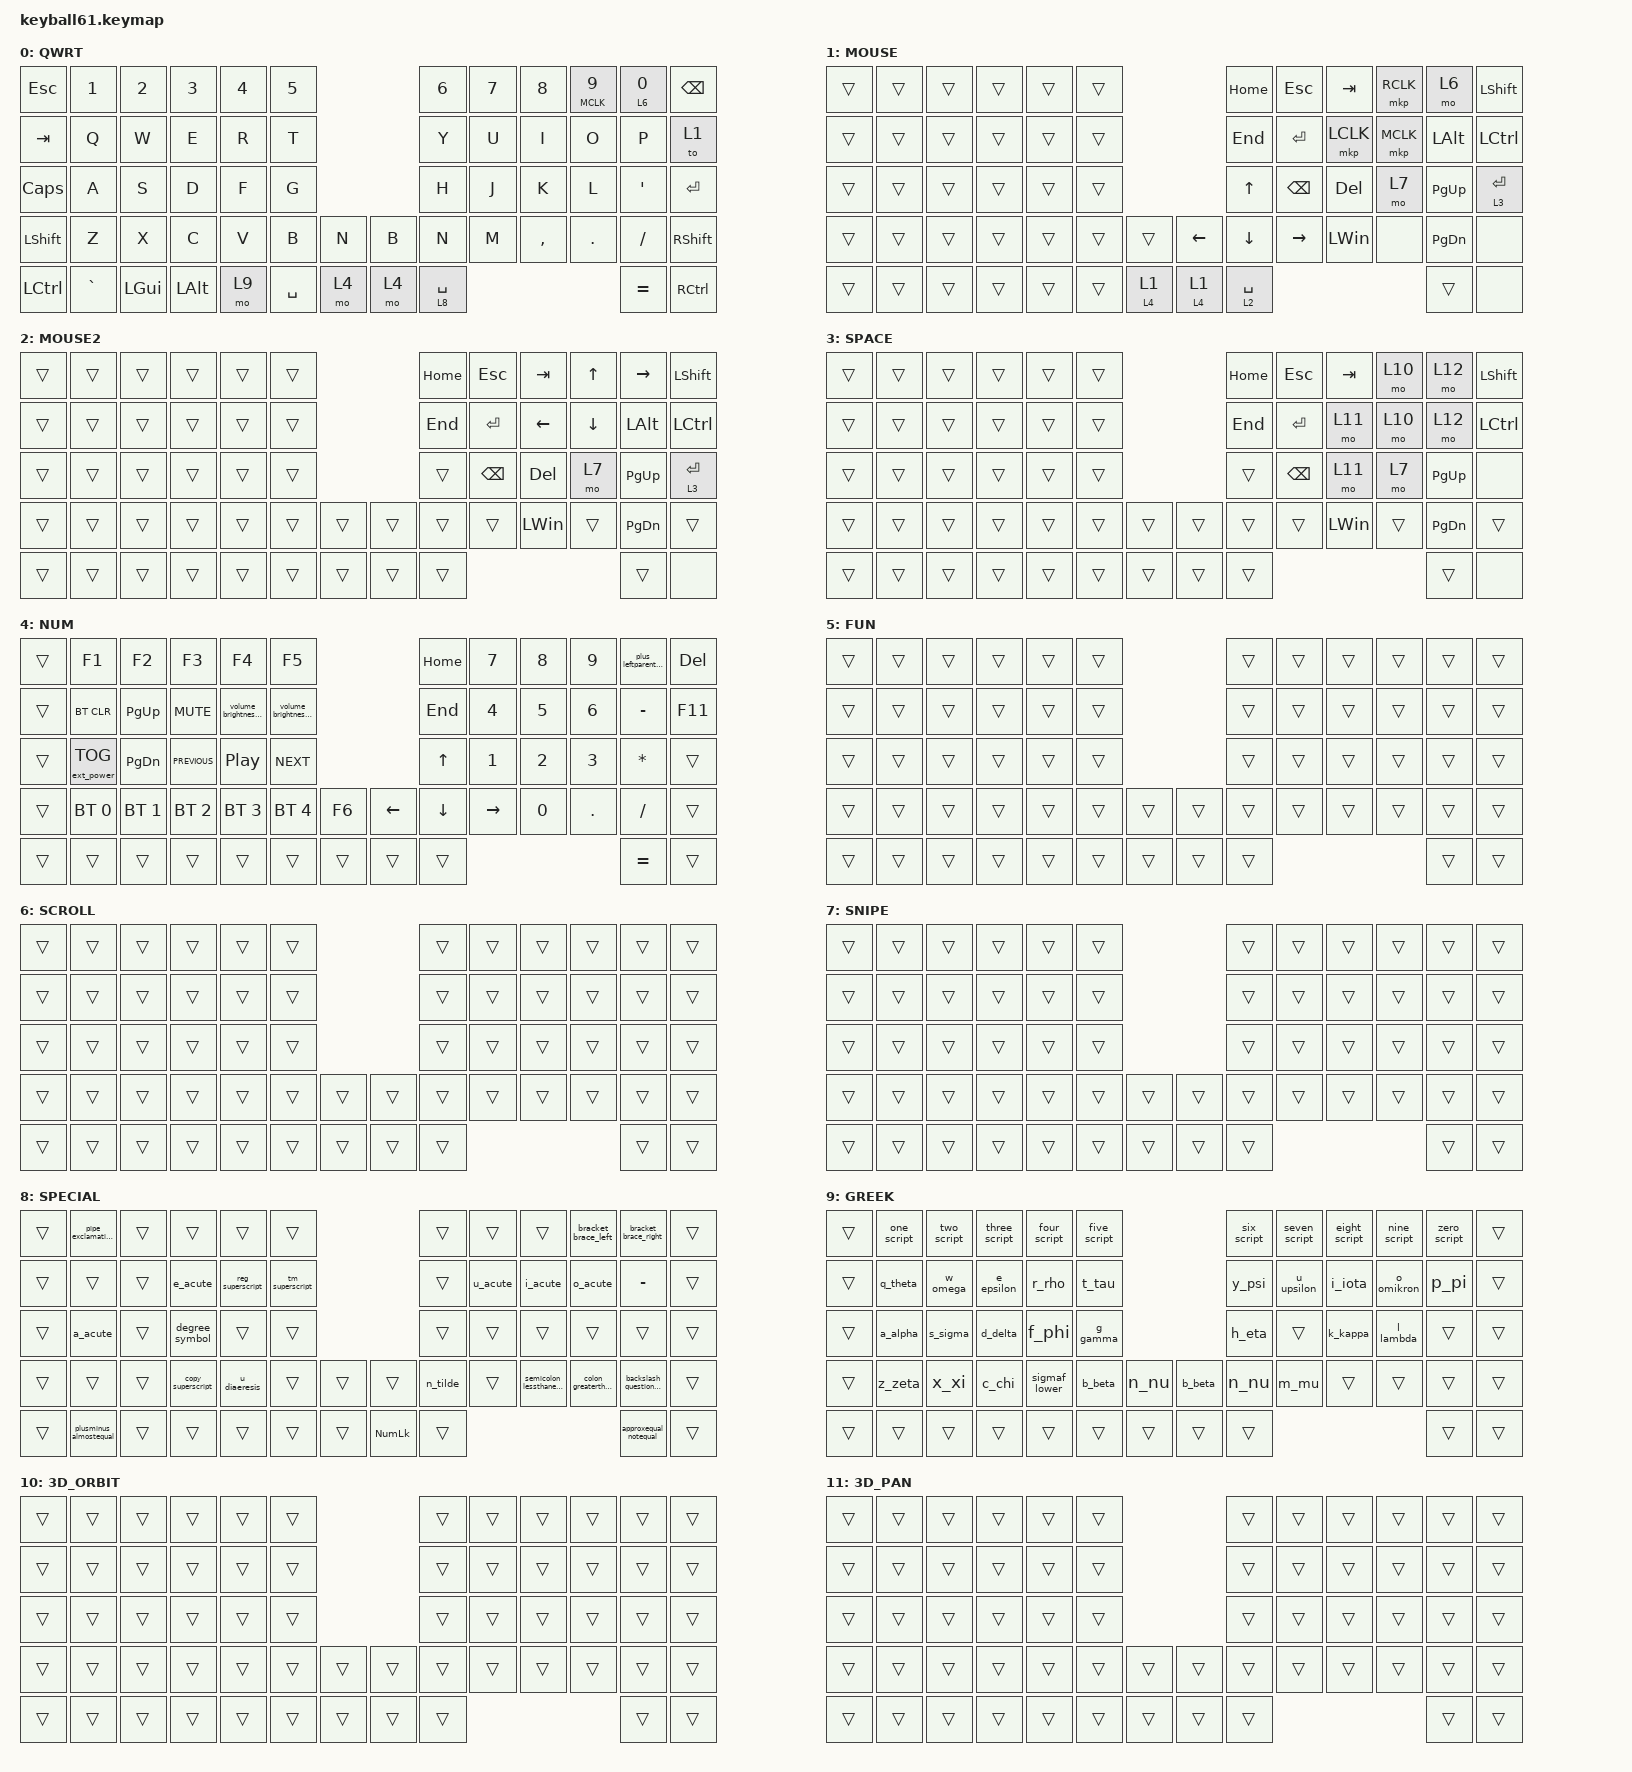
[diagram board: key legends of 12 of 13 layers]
#define DEFAULT 0
#define SYM     1
#define FUN     2
#define MOUSE   3
#define SCROLL  4
#define SNIPE   5

#include <dt-bindings/zmk/mouse.h>

//#include <dt-bindings/zmk/pointers.h>

#include <behaviors.dtsi>
#include <dt-bindings/zmk/bt.h>
#include <dt-bindings/zmk/ext_power.h>
#include <dt-bindings/zmk/keys.h>
#include <dt-bindings/zmk/pointing.h>

&lt {
    tapping-term-ms = <240>;
    flavor = "balanced";
    quick-tap-ms = <150>;
};

&mt {
    tapping-term-ms = <300>;
    flavor = "tap-preferred";
    quick-tap-ms = <150>;
};

/ {
    combos { compatible = "zmk,combos"; };

    behaviors {
        lmt0: lmt0 {
            compatible = "zmk,behavior-hold-tap";
            label = "Tap=&tog; Hold=&mo";
            bindings = <&mo>, <&tog>;

            #binding-cells = <2>;
            tapping-term-ms = <200>;
            flavor = "balanced";
        };

        lmt1: lmt1 {
            compatible = "zmk,behavior-hold-tap";
            label = "Tap=&tog; Hold=&kp";
            bindings = <&kp>, <&tog>;

            #binding-cells = <2>;
            tapping-term-ms = <250>;
            flavor = "balanced";
        };

        lmt2: lmt2 {
            compatible = "zmk,behavior-hold-tap";
            label = "Tap=&kp; Hold=&mkp";
            bindings = <&mkp>, <&kp>;

            #binding-cells = <2>;
            tapping-term-ms = <250>;
            flavor = "balanced";
        };

        td0: td0 {
            compatible = "zmk,behavior-tap-dance";
            label = "1tap=shift;2tap=&tog4";
            #binding-cells = <0>;
            bindings = <&kp LEFT_CONTROL>, <&tog 1>;
        };

        plus_leftparenthesis: plus_leftparenthesis {
            compatible = "zmk,behavior-mod-morph";
            label = "PLUS_LEFTPARENTHESIS";
            bindings = <&kp PLUS>, <&kp RIGHT_PARENTHESIS>;

            #binding-cells = <0>;
            mods = <(MOD_LSFT|MOD_RSFT)>;
        };

        volume_brightness_down: volume_brightness_down {
            compatible = "zmk,behavior-mod-morph";
            label = "VOLUME_BRIGHTNESS_DOWN";
            bindings = <&kp C_VOLUME_DOWN>, <&kp C_BRIGHTNESS_DEC>;

            #binding-cells = <0>;
            mods = <(MOD_LSFT|MOD_RSFT)>;
        };

        volume_brightness_up: volume_brightness_up {
            compatible = "zmk,behavior-mod-morph";
            label = "VOLUME_BRIGHTNESS_UP";
            bindings = <&kp C_VOLUME_UP>, <&kp C_BRIGHTNESS_INC>;

            #binding-cells = <0>;
            mods = <(MOD_LSFT|MOD_RSFT)>;
        };

        n_tilde: n_tilde {
            compatible = "zmk,behavior-mod-morph";
            label = "N_TILDE";
            bindings = <&n_tilde_lower>, <&n_tilde_upper>;

            #binding-cells = <0>;
            mods = <(MOD_LSFT|MOD_RSFT)>;
        };

        a_acute: a_acute {
            compatible = "zmk,behavior-mod-morph";
            label = "A_ACUTE";
            bindings = <&a_acute_lower>, <&a_acute_upper>;

            #binding-cells = <0>;
            mods = <(MOD_LSFT|MOD_RCTL)>;
        };

        e_acute: e_acute {
            compatible = "zmk,behavior-mod-morph";
            label = "E_ACUTE";
            bindings = <&e_acute_lower>, <&e_acute_upper>;

            #binding-cells = <0>;
            mods = <(MOD_LSFT|MOD_RCTL)>;
        };

        i_acute: i_acute {
            compatible = "zmk,behavior-mod-morph";
            label = "I_ACUTE";
            bindings = <&i_acute_lower>, <&i_acute_upper>;

            #binding-cells = <0>;
            mods = <(MOD_LSFT|MOD_RCTL)>;
        };

        o_acute: o_acute {
            compatible = "zmk,behavior-mod-morph";
            label = "O_ACUTE";
            bindings = <&o_acute_lower>, <&o_acute_upper>;

            #binding-cells = <0>;
            mods = <(MOD_LSFT|MOD_RCTL)>;
        };

        u_acute: u_acute {
            compatible = "zmk,behavior-mod-morph";
            label = "U_ACUTE";
            bindings = <&u_acute_lower>, <&u_acute_upper>;

            #binding-cells = <0>;
            mods = <(MOD_LSFT|MOD_RCTL)>;
        };

        u_diaeresis: u_diaeresis {
            compatible = "zmk,behavior-mod-morph";
            label = "U_DIAERESIS";
            bindings = <&u_diaeresis_lower>, <&u_diaeresis_upper>;

            #binding-cells = <0>;
            mods = <(MOD_LSFT|MOD_RCTL)>;
        };

        backslash_questionmarkreverse: backslash_questionmarkreverse {
            compatible = "zmk,behavior-mod-morph";
            label = "BACKSLASH_QUESTIONMARKREVERSE";
            bindings = <&kp BACKSLASH>, <&question_mark_reverse>;

            #binding-cells = <0>;
            mods = <(MOD_LSFT|MOD_RSFT)>;
        };

        semicolon_lessthanequal: semicolon_lessthanequal {
            compatible = "zmk,behavior-mod-morph";
            label = "SEMICOLON_LESSTHANEQUAL";
            bindings = <&kp SEMICOLON>, <&less_than_equal>;

            #binding-cells = <0>;
            mods = <(MOD_LSFT|MOD_RSFT)>;
        };

        colon_greaterthanequal: colon_greaterthanequal {
            compatible = "zmk,behavior-mod-morph";
            label = "COLON_GREATERTHANEQUAL";
            bindings = <&kp COLON>, <&greater_than_equal>;

            #binding-cells = <0>;
            mods = <(MOD_LSFT|MOD_RSFT)>;
        };

        approxequal_notequal: approxequal_notequal {
            compatible = "zmk,behavior-mod-morph";
            label = "APPROXEQUAL_NOTEQUAL";
            bindings = <&approx_equal>, <&not_equal>;

            #binding-cells = <0>;
            mods = <(MOD_LSFT|MOD_RSFT)>;
        };

        plusminus_almostequal: plusminus_almostequal {
            compatible = "zmk,behavior-mod-morph";
            label = "PLUSMINUS_ALMOSTEQUAL";
            bindings = <&plus_minus>, <&almost_equal>;

            #binding-cells = <0>;
            mods = <(MOD_LSFT|MOD_RSFT)>;
        };

        pipe_exclamationmarkreverse: pipe_exclamationmarkreverse {
            compatible = "zmk,behavior-mod-morph";
            label = "PIPE_EXCLAMATIONMARKREVERSE";
            bindings = <&kp PIPE>, <&exclamation_mark_reverse>;

            #binding-cells = <0>;
            mods = <(MOD_LSFT|MOD_RSFT)>;
        };

        bracket_brace_left: bracket_brace_left {
            compatible = "zmk,behavior-mod-morph";
            label = "BRACKET_BRACE_LEFT";
            bindings = <&kp LEFT_BRACKET>, <&kp LEFT_BRACE>;

            #binding-cells = <0>;
            mods = <(MOD_LSFT|MOD_RSFT)>;
        };

        bracket_brace_right: bracket_brace_right {
            compatible = "zmk,behavior-mod-morph";
            label = "BRACKET_BRACE_RIGHT";
            bindings = <&kp RIGHT_BRACKET>, <&kp RIGHT_BRACE>;

            #binding-cells = <0>;
            mods = <(MOD_LSFT|MOD_RSFT)>;
        };

        one_script: one_script {
            compatible = "zmk,behavior-mod-morph";
            label = "ONE_SCRIPT";
            bindings = <&one_subscript>, <&one_superscript>;

            #binding-cells = <0>;
            mods = <(MOD_LSFT|MOD_RSFT)>;
        };

        two_script: two_script {
            compatible = "zmk,behavior-mod-morph";
            label = "TWO_SCRIPT";
            bindings = <&two_subscript>, <&two_superscript>;

            #binding-cells = <0>;
            mods = <(MOD_LSFT|MOD_RSFT)>;
        };

        three_script: three_script {
            compatible = "zmk,behavior-mod-morph";
            label = "THREE_SCRIPT";
            bindings = <&three_subscript>, <&three_superscript>;

            #binding-cells = <0>;
            mods = <(MOD_LSFT|MOD_RSFT)>;
        };

        four_script: four_script {
            compatible = "zmk,behavior-mod-morph";
            label = "FOUR_SCRIPT";
            bindings = <&four_subscript>, <&four_superscript>;

            #binding-cells = <0>;
            mods = <(MOD_LSFT|MOD_RSFT)>;
        };

        five_script: five_script {
            compatible = "zmk,behavior-mod-morph";
            label = "FIVE_SCRIPT";
            bindings = <&five_subscript>, <&five_superscript>;

            #binding-cells = <0>;
            mods = <(MOD_LSFT|MOD_RSFT)>;
        };

        six_script: six_script {
            compatible = "zmk,behavior-mod-morph";
            label = "SIX_SCRIPT";
            bindings = <&six_subscript>, <&six_superscript>;

            #binding-cells = <0>;
            mods = <(MOD_LSFT|MOD_RSFT)>;
        };

        seven_script: seven_script {
            compatible = "zmk,behavior-mod-morph";
            label = "SEVEN_SCRIPT";
            bindings = <&seven_subscript>, <&seven_superscript>;

            #binding-cells = <0>;
            mods = <(MOD_LSFT|MOD_RSFT)>;
        };

        eight_script: eight_script {
            compatible = "zmk,behavior-mod-morph";
            label = "EIGHT_SCRIPT";
            bindings = <&eight_subscript>, <&eight_superscript>;

            #binding-cells = <0>;
            mods = <(MOD_LSFT|MOD_RSFT)>;
        };

        nine_script: nine_script {
            compatible = "zmk,behavior-mod-morph";
            label = "NINE_SCRIPT";
            bindings = <&nine_subscript>, <&nine_superscript>;

            #binding-cells = <0>;
            mods = <(MOD_LSFT|MOD_RSFT)>;
        };

        zero_script: zero_script {
            compatible = "zmk,behavior-mod-morph";
            label = "ZERO_SCRIPT";
            bindings = <&zero_subscript>, <&zero_superscript>;

            #binding-cells = <0>;
            mods = <(MOD_LSFT|MOD_RSFT)>;
        };

        a_alpha: a_alpha {
            compatible = "zmk,behavior-mod-morph";
            label = "A_ALPHA";
            bindings = <&alpha_lower>, <&alpha_upper>;

            #binding-cells = <0>;
            mods = <(MOD_LSFT|MOD_RSFT)>;
        };

        b_beta: b_beta {
            compatible = "zmk,behavior-mod-morph";
            label = "B_BETA";
            bindings = <&beta_lower>, <&beta_upper>;

            #binding-cells = <0>;
            mods = <(MOD_LSFT|MOD_RSFT)>;
        };

        g_gamma: g_gamma {
            compatible = "zmk,behavior-mod-morph";
            label = "G_GAMMA";
            bindings = <&gamma_lower>, <&gamma_upper>;

            #binding-cells = <0>;
            mods = <(MOD_LSFT|MOD_RSFT)>;
        };

        d_delta: d_delta {
            compatible = "zmk,behavior-mod-morph";
            label = "D_DELTA";
            bindings = <&delta_lower>, <&delta_upper>;

            #binding-cells = <0>;
            mods = <(MOD_LSFT|MOD_RSFT)>;
        };

        e_epsilon: e_epsilon {
            compatible = "zmk,behavior-mod-morph";
            label = "E_EPSILON";
            bindings = <&epsilon_lower>, <&epsilon_upper>;

            #binding-cells = <0>;
            mods = <(MOD_LSFT|MOD_RSFT)>;
        };

        z_zeta: z_zeta {
            compatible = "zmk,behavior-mod-morph";
            label = "Z_ZETA";
            bindings = <&zeta_lower>, <&zeta_upper>;

            #binding-cells = <0>;
            mods = <(MOD_LSFT|MOD_RSFT)>;
        };

        h_eta: h_eta {
            compatible = "zmk,behavior-mod-morph";
            label = "H_ETA";
            bindings = <&eta_lower>, <&eta_upper>;

            #binding-cells = <0>;
            mods = <(MOD_LSFT|MOD_RSFT)>;
        };

        q_theta: q_theta {
            compatible = "zmk,behavior-mod-morph";
            label = "Q_THETA";
            bindings = <&theta_lower>, <&theta_upper>;

            #binding-cells = <0>;
            mods = <(MOD_LSFT|MOD_RSFT)>;
        };

        i_iota: i_iota {
            compatible = "zmk,behavior-mod-morph";
            label = "I_IOTA";
            bindings = <&iota_lower>, <&iota_upper>;

            #binding-cells = <0>;
            mods = <(MOD_LSFT|MOD_RSFT)>;
        };

        k_kappa: k_kappa {
            compatible = "zmk,behavior-mod-morph";
            label = "K_KAPPA";
            bindings = <&kappa_lower>, <&kappa_upper>;

            #binding-cells = <0>;
            mods = <(MOD_LSFT|MOD_RSFT)>;
        };

        l_lambda: l_lambda {
            compatible = "zmk,behavior-mod-morph";
            label = "L_LAMBDA";
            bindings = <&lambda_lower>, <&lambda_upper>;

            #binding-cells = <0>;
            mods = <(MOD_LSFT|MOD_RSFT)>;
        };

        m_mu: m_mu {
            compatible = "zmk,behavior-mod-morph";
            label = "M_MU";
            bindings = <&mu_lower>, <&mu_upper>;

            #binding-cells = <0>;
            mods = <(MOD_LSFT|MOD_RSFT)>;
        };

        n_nu: n_nu {
            compatible = "zmk,behavior-mod-morph";
            label = "N_NU";
            bindings = <&nu_lower>, <&nu_upper>;

            #binding-cells = <0>;
            mods = <(MOD_LSFT|MOD_RSFT)>;
        };

        x_xi: x_xi {
            compatible = "zmk,behavior-mod-morph";
            label = "X_XI";
            bindings = <&xi_lower>, <&xi_upper>;

            #binding-cells = <0>;
            mods = <(MOD_LSFT|MOD_RSFT)>;
        };

        o_omikron: o_omikron {
            compatible = "zmk,behavior-mod-morph";
            label = "O_OMIKRON";
            bindings = <&omicron_lower>, <&omicron_upper>;

            #binding-cells = <0>;
            mods = <(MOD_LSFT|MOD_RSFT)>;
        };

        p_pi: p_pi {
            compatible = "zmk,behavior-mod-morph";
            label = "P_PI";
            bindings = <&pi_lower>, <&pi_upper>;

            #binding-cells = <0>;
            mods = <(MOD_LSFT|MOD_RSFT)>;
        };

        r_rho: r_rho {
            compatible = "zmk,behavior-mod-morph";
            label = "R_RHO";
            bindings = <&rho_lower>, <&rho_upper>;

            #binding-cells = <0>;
            mods = <(MOD_LSFT|MOD_RSFT)>;
        };

        s_sigma: s_sigma {
            compatible = "zmk,behavior-mod-morph";
            label = "S_SIGMA";
            bindings = <&sigma_lower>, <&sigma_upper>;

            #binding-cells = <0>;
            mods = <(MOD_LSFT|MOD_RSFT)>;
        };

        t_tau: t_tau {
            compatible = "zmk,behavior-mod-morph";
            label = "T_TAU";
            bindings = <&tau_lower>, <&tau_upper>;

            #binding-cells = <0>;
            mods = <(MOD_LSFT|MOD_RSFT)>;
        };

        u_upsilon: u_upsilon {
            compatible = "zmk,behavior-mod-morph";
            label = "U_UPSILON";
            bindings = <&upsilon_lower>, <&upsilon_upper>;

            #binding-cells = <0>;
            mods = <(MOD_LSFT|MOD_RSFT)>;
        };

        f_phi: f_phi {
            compatible = "zmk,behavior-mod-morph";
            label = "F_PHI";
            bindings = <&phi_lower>, <&phi_upper>;

            #binding-cells = <0>;
            mods = <(MOD_LSFT|MOD_RSFT)>;
        };

        c_chi: c_chi {
            compatible = "zmk,behavior-mod-morph";
            label = "C_CHI";
            bindings = <&chi_lower>, <&chi_upper>;

            #binding-cells = <0>;
            mods = <(MOD_LSFT|MOD_RSFT)>;
        };

        y_psi: y_psi {
            compatible = "zmk,behavior-mod-morph";
            label = "Y_PSI";
            bindings = <&psi_lower>, <&psi_upper>;

            #binding-cells = <0>;
            mods = <(MOD_LSFT|MOD_RSFT)>;
        };

        w_omega: w_omega {
            compatible = "zmk,behavior-mod-morph";
            label = "W_OMEGA";
            bindings = <&omega_lower>, <&omega_upper>;

            #binding-cells = <0>;
            mods = <(MOD_LSFT|MOD_RSFT)>;
        };
    };

    macros {
        n_tilde_lower: n_tilde_lower {
            compatible = "zmk,behavior-macro";
            #binding-cells = <0>;
            bindings =
                <&macro_press>,
                <&kp LEFT_ALT>,
                <&macro_tap>,
                <&kp KP_NUMBER_1 &kp KP_NUMBER_6 &kp KP_NUMBER_4>,
                <&macro_release>,
                <&kp LALT>;

            label = "N_TILDE_LOWER";
            wait-ms = <1>;
            tap-ms = <1>;
        };

        n_tilde_upper: n_tilde_upper {
            compatible = "zmk,behavior-macro";
            #binding-cells = <0>;
            bindings =
                <&macro_press>,
                <&kp LEFT_ALT>,
                <&macro_tap>,
                <&kp KP_NUMBER_1 &kp KP_NUMBER_6 &kp KP_NUMBER_5>,
                <&macro_release>,
                <&kp LALT>;

            label = "N_TILDE_UPPER";
            wait-ms = <1>;
            tap-ms = <1>;
        };

        a_acute_lower: a_acute_lower {
            compatible = "zmk,behavior-macro";
            #binding-cells = <0>;
            bindings =
                <&macro_press>,
                <&kp LEFT_ALT>,
                <&macro_tap>,
                <&kp KP_NUMBER_1 &kp KP_NUMBER_6 &kp KP_NUMBER_0>,
                <&macro_release>,
                <&kp LEFT_ALT>;

            label = "A_ACUTE_LOWER";
            wait-ms = <1>;
            tap-ms = <1>;
        };

        a_acute_upper: a_acute_upper {
            compatible = "zmk,behavior-macro";
            #binding-cells = <0>;
            bindings =
                <&macro_press>,
                <&kp LEFT_ALT>,
                <&macro_tap>,
                <&kp KP_NUMBER_0 &kp KP_NUMBER_1 &kp KP_NUMBER_9 &kp KP_NUMBER_3>,
                <&macro_release>,
                <&kp LEFT_ALT>;

            label = "A_ACUTE_UPPER";
            wait-ms = <1>;
            tap-ms = <1>;
        };

        e_acute_lower: e_acute_lower {
            compatible = "zmk,behavior-macro";
            #binding-cells = <0>;
            bindings =
                <&macro_press>,
                <&kp LEFT_ALT>,
                <&macro_tap>,
                <&kp KP_NUMBER_1 &kp KP_NUMBER_3 &kp KP_NUMBER_0>,
                <&macro_release>,
                <&kp LEFT_ALT>;

            label = "E_ACUTE_LOWER";
            wait-ms = <1>;
            tap-ms = <1>;
        };

        e_acute_upper: e_acute_upper {
            compatible = "zmk,behavior-macro";
            #binding-cells = <0>;
            bindings =
                <&macro_press>,
                <&kp LEFT_ALT>,
                <&macro_tap>,
                <&kp KP_NUMBER_1 &kp KP_NUMBER_4 &kp KP_NUMBER_4>,
                <&macro_release>,
                <&kp LEFT_ALT>;

            label = "E_ACUTE_UPPER";
            wait-ms = <1>;
            tap-ms = <1>;
        };

        i_acute_lower: i_acute_lower {
            compatible = "zmk,behavior-macro";
            #binding-cells = <0>;
            bindings =
                <&macro_press>,
                <&kp LEFT_ALT>,
                <&macro_tap>,
                <&kp KP_NUMBER_1 &kp KP_NUMBER_6 &kp KP_NUMBER_1>,
                <&macro_release>,
                <&kp LEFT_ALT>;

            label = "I_ACUTE_LOWER";
            wait-ms = <1>;
            tap-ms = <1>;
        };

        i_acute_upper: i_acute_upper {
            compatible = "zmk,behavior-macro";
            #binding-cells = <0>;
            bindings =
                <&macro_press>,
                <&kp LEFT_ALT>,
                <&macro_tap>,
                <&kp KP_NUMBER_0 &kp KP_NUMBER_2 &kp KP_NUMBER_0 &kp KP_NUMBER_5>,
                <&macro_release>,
                <&kp LEFT_ALT>;

            label = "I_ACUTE_UPPER";
            wait-ms = <1>;
            tap-ms = <1>;
        };

        o_acute_lower: o_acute_lower {
            compatible = "zmk,behavior-macro";
            #binding-cells = <0>;
            bindings =
                <&macro_press>,
                <&kp LEFT_ALT>,
                <&macro_tap>,
                <&kp KP_NUMBER_1 &kp KP_NUMBER_6 &kp KP_NUMBER_2>,
                <&macro_release>,
                <&kp LEFT_ALT>;

            label = "O_ACUTE_LOWER";
            wait-ms = <1>;
            tap-ms = <1>;
        };

        o_acute_upper: o_acute_upper {
            compatible = "zmk,behavior-macro";
            #binding-cells = <0>;
            bindings =
                <&macro_press>,
                <&kp LEFT_ALT>,
                <&macro_tap>,
                <&kp KP_NUMBER_0 &kp KP_NUMBER_2 &kp KP_NUMBER_1 &kp KP_NUMBER_1>,
                <&macro_release>,
                <&kp LEFT_ALT>;

            label = "O_ACUTE_UPPER";
            wait-ms = <1>;
            tap-ms = <1>;
        };

        u_acute_lower: u_acute_lower {
            compatible = "zmk,behavior-macro";
            #binding-cells = <0>;
            bindings =
                <&macro_press>,
                <&kp LEFT_ALT>,
                <&macro_tap>,
                <&kp KP_NUMBER_1 &kp KP_NUMBER_6 &kp KP_NUMBER_3>,
                <&macro_release>,
                <&kp LEFT_ALT>;

            label = "U_ACUTE_LOWER";
            wait-ms = <1>;
            tap-ms = <1>;
        };

        u_acute_upper: u_acute_upper {
            compatible = "zmk,behavior-macro";
            #binding-cells = <0>;
            bindings =
                <&macro_press>,
                <&kp LEFT_ALT>,
                <&macro_tap>,
                <&kp KP_NUMBER_0 &kp KP_NUMBER_2 &kp KP_NUMBER_1 &kp KP_NUMBER_8>,
                <&macro_release>,
                <&kp LEFT_ALT>;

            label = "U_ACUTE_UPPER";
            wait-ms = <1>;
            tap-ms = <1>;
        };

        u_diaeresis_lower: u_diaeresis_lower {
            compatible = "zmk,behavior-macro";
            #binding-cells = <0>;
            bindings =
                <&macro_press>,
                <&kp LEFT_ALT>,
                <&macro_tap>,
                <&kp KP_NUMBER_1 &kp KP_NUMBER_2 &kp KP_NUMBER_9>,
                <&macro_release>,
                <&kp LEFT_ALT>;

            label = "U_DIAERESIS_LOWER";
            wait-ms = <1>;
            tap-ms = <1>;
        };

        u_diaeresis_upper: u_diaeresis_upper {
            compatible = "zmk,behavior-macro";
            #binding-cells = <0>;
            bindings =
                <&macro_press>,
                <&kp LEFT_ALT>,
                <&macro_tap>,
                <&kp KP_NUMBER_1 &kp KP_NUMBER_5 &kp KP_NUMBER_4>,
                <&macro_release>,
                <&kp LEFT_ALT>;

            label = "U_DIAERESIS_UPPER";
            wait-ms = <1>;
            tap-ms = <1>;
        };

        question_mark_reverse: question_mark_reverse {
            compatible = "zmk,behavior-macro";
            #binding-cells = <0>;
            bindings =
                <&macro_press>,
                <&kp LEFT_ALT>,
                <&macro_tap>,
                <&kp KP_NUMBER_1 &kp KP_NUMBER_6 &kp KP_NUMBER_8>,
                <&macro_release>,
                <&kp LEFT_ALT>;

            label = "QUESTION_MARK_REVERSE";
            wait-ms = <1>;
            tap-ms = <1>;
        };

        less_than_equal: less_than_equal {
            compatible = "zmk,behavior-macro";
            #binding-cells = <0>;
            bindings =
                <&macro_press>,
                <&kp LEFT_ALT>,
                <&macro_tap>,
                <&kp KP_NUMBER_2 &kp KP_NUMBER_4 &kp KP_NUMBER_3>,
                <&macro_release>,
                <&kp LEFT_ALT>;

            label = "LESS_THAN_EQUAL";
            wait-ms = <1>;
            tap-ms = <1>;
        };

        greater_than_equal: greater_than_equal {
            compatible = "zmk,behavior-macro";
            #binding-cells = <0>;
            bindings =
                <&macro_press>,
                <&kp LEFT_ALT>,
                <&macro_tap>,
                <&kp KP_NUMBER_2 &kp KP_NUMBER_4 &kp KP_NUMBER_2>,
                <&macro_release>,
                <&kp LEFT_ALT>;

            label = "GREATER_THAN_EQUAL";
            wait-ms = <1>;
            tap-ms = <1>;
        };

        approx_equal: approx_equal {
            compatible = "zmk,behavior-macro";
            #binding-cells = <0>;
            bindings =
                <&macro_press>,
                <&kp LEFT_ALT>,
                <&macro_tap>,
                <&kp KP_NUMBER_8 &kp KP_NUMBER_7 &kp KP_NUMBER_7 &kp KP_NUMBER_3>,
                <&macro_release>,
                <&kp LEFT_ALT>;

            label = "APPROX_EQUAL";
            wait-ms = <1>;
            tap-ms = <1>;
        };

        not_equal: not_equal {
            compatible = "zmk,behavior-macro";
            #binding-cells = <0>;
            bindings =
                <&macro_press>,
                <&kp LEFT_ALT>,
                <&macro_tap>,
                <&kp KP_NUMBER_8 &kp KP_NUMBER_8 &kp KP_NUMBER_0 &kp KP_NUMBER_0>,
                <&macro_release>,
                <&kp LEFT_ALT>;

            label = "NOT_EQUAL";
            wait-ms = <1>;
            tap-ms = <1>;
        };

        exclamation_mark_reverse: exclamation_mark_reverse {
            compatible = "zmk,behavior-macro";
            #binding-cells = <0>;
            bindings =
                <&macro_press>,
                <&kp LEFT_ALT>,
                <&macro_tap>,
                <&kp KP_NUMBER_1 &kp KP_NUMBER_7 &kp KP_NUMBER_3>,
                <&macro_release>,
                <&kp LEFT_ALT>;

            label = "EXCLAMATION_MARK_REVERSE";
            wait-ms = <1>;
            tap-ms = <1>;
        };

        almost_equal: almost_equal {
            compatible = "zmk,behavior-macro";
            #binding-cells = <0>;
            bindings =
                <&macro_press>,
                <&kp LEFT_ALT>,
                <&macro_tap>,
                <&kp KP_NUMBER_2 &kp KP_NUMBER_4 &kp KP_NUMBER_7>,
                <&macro_release>,
                <&kp LEFT_ALT>;

            label = "ALMOST_EQUAL";
            wait-ms = <1>;
            tap-ms = <1>;
        };

        degree_symbol: degree_symbol {
            compatible = "zmk,behavior-macro";
            #binding-cells = <0>;
            bindings =
                <&macro_press>,
                <&kp LEFT_ALT>,
                <&macro_tap>,
                <&kp KP_NUMBER_2 &kp KP_NUMBER_4 &kp KP_NUMBER_8>,
                <&macro_release>,
                <&kp LEFT_ALT>;

            label = "DEGREE_SYMBOL";
            wait-ms = <1>;
            tap-ms = <1>;
        };

        plus_minus: plus_minus {
            compatible = "zmk,behavior-macro";
            #binding-cells = <0>;
            bindings =
                <&macro_press>,
                <&kp LEFT_ALT>,
                <&macro_tap>,
                <&kp KP_NUMBER_0 &kp KP_NUMBER_1 &kp KP_NUMBER_7 &kp KP_NUMBER_7>,
                <&macro_release>,
                <&kp LEFT_ALT>;

            label = "PLUS_MINUS";
            wait-ms = <1>;
            tap-ms = <1>;
        };

        zero_superscript: zero_superscript {
            compatible = "zmk,behavior-macro";
            #binding-cells = <0>;
            bindings =
                <&macro_press>,
                <&kp LEFT_ALT>,
                <&macro_tap>,
                <&kp KP_NUMBER_8 &kp KP_NUMBER_3 &kp KP_NUMBER_0 &kp KP_NUMBER_4>,
                <&macro_release>,
                <&kp LEFT_ALT>;

            label = "ZERO_SUPERSCRIPT";
            wait-ms = <1>;
            tap-ms = <1>;
        };

        one_superscript: one_superscript {
            compatible = "zmk,behavior-macro";
            #binding-cells = <0>;
            bindings =
                <&macro_press>,
                <&kp LEFT_ALT>,
                <&macro_tap>,
                <&kp KP_NUMBER_0 &kp KP_NUMBER_1 &kp KP_NUMBER_8 &kp KP_NUMBER_5>,
                <&macro_release>,
                <&kp LEFT_ALT>;

            label = "ONE_SUPERSCRIPT";
            wait-ms = <1>;
            tap-ms = <1>;
        };

        two_superscript: two_superscript {
            compatible = "zmk,behavior-macro";
            #binding-cells = <0>;
            bindings =
                <&macro_press>,
                <&kp LEFT_ALT>,
                <&macro_tap>,
                <&kp KP_NUMBER_0 &kp KP_NUMBER_1 &kp KP_NUMBER_7 &kp KP_NUMBER_8>,
                <&macro_release>,
                <&kp LEFT_ALT>;

            label = "TWO_SUPERSCRIPT";
            wait-ms = <1>;
            tap-ms = <1>;
        };

        three_superscript: three_superscript {
            compatible = "zmk,behavior-macro";
            #binding-cells = <0>;
            bindings =
                <&macro_press>,
                <&kp LEFT_ALT>,
                <&macro_tap>,
                <&kp KP_NUMBER_0 &kp KP_NUMBER_1 &kp KP_NUMBER_7 &kp KP_NUMBER_9>,
                <&macro_release>,
                <&kp LEFT_ALT>;

            label = "THREE_SUPERSCRIPT";
            wait-ms = <1>;
            tap-ms = <1>;
        };

        four_superscript: four_superscript {
            compatible = "zmk,behavior-macro";
            #binding-cells = <0>;
            bindings =
                <&macro_press>,
                <&kp LEFT_ALT>,
                <&macro_tap>,
                <&kp KP_NUMBER_8 &kp KP_NUMBER_3 &kp KP_NUMBER_0 &kp KP_NUMBER_8>,
                <&macro_release>,
                <&kp LEFT_ALT>;

            label = "FOUR_SUPERSCRIPT";
            wait-ms = <1>;
            tap-ms = <1>;
        };

        five_superscript: five_superscript {
            compatible = "zmk,behavior-macro";
            #binding-cells = <0>;
            bindings =
                <&macro_press>,
                <&kp LEFT_ALT>,
                <&macro_tap>,
                <&kp KP_NUMBER_8 &kp KP_NUMBER_3 &kp KP_NUMBER_0 &kp KP_NUMBER_9>,
                <&macro_release>,
                <&kp LEFT_ALT>;

            label = "FIVE_SUPERSCRIPT";
            wait-ms = <1>;
            tap-ms = <1>;
        };

        six_superscript: six_superscript {
            compatible = "zmk,behavior-macro";
            #binding-cells = <0>;
            bindings =
                <&macro_press>,
                <&kp LEFT_ALT>,
                <&macro_tap>,
                <&kp KP_NUMBER_8 &kp KP_NUMBER_3 &kp KP_NUMBER_1 &kp KP_NUMBER_0>,
                <&macro_release>,
                <&kp LEFT_ALT>;

            label = "SIX_SUPERSCRIPT";
            wait-ms = <1>;
            tap-ms = <1>;
        };

        seven_superscript: seven_superscript {
            compatible = "zmk,behavior-macro";
            #binding-cells = <0>;
            bindings =
                <&macro_press>,
                <&kp LEFT_ALT>,
                <&macro_tap>,
                <&kp KP_NUMBER_8 &kp KP_NUMBER_3 &kp KP_NUMBER_1 &kp KP_NUMBER_1>,
                <&macro_release>,
                <&kp LEFT_ALT>;

            label = "SEVEN_SUPERSCRIPT";
            wait-ms = <1>;
            tap-ms = <1>;
        };

        eight_superscript: eight_superscript {
            compatible = "zmk,behavior-macro";
            #binding-cells = <0>;
            bindings =
                <&macro_press>,
                <&kp LEFT_ALT>,
                <&macro_tap>,
                <&kp KP_NUMBER_8 &kp KP_NUMBER_3 &kp KP_NUMBER_1 &kp KP_NUMBER_2>,
                <&macro_release>,
                <&kp LEFT_ALT>;

            label = "EIGHT_SUPERSCRIPT";
            wait-ms = <1>;
            tap-ms = <1>;
        };

        nine_superscript: nine_superscript {
            compatible = "zmk,behavior-macro";
            #binding-cells = <0>;
            bindings =
                <&macro_press>,
                <&kp LEFT_ALT>,
                <&macro_tap>,
                <&kp KP_NUMBER_8 &kp KP_NUMBER_3 &kp KP_NUMBER_1 &kp KP_NUMBER_3>,
                <&macro_release>,
                <&kp LEFT_ALT>;

            label = "NINE_SUPERSCRIPT";
            wait-ms = <1>;
            tap-ms = <1>;
        };

        alpha_lower: alpha_lower {
            compatible = "zmk,behavior-macro";
            #binding-cells = <0>;
            bindings =
                <&macro_press>,
                <&kp LEFT_ALT>,
                <&macro_tap>,
                <&kp KP_NUMBER_2 &kp KP_NUMBER_2 &kp KP_NUMBER_4>,
                <&macro_release>,
                <&kp LEFT_ALT>;

            label = "ALPHA_LOWER";
            wait-ms = <1>;
            tap-ms = <1>;
        };

        alpha_upper: alpha_upper {
            compatible = "zmk,behavior-macro";
            #binding-cells = <0>;
            bindings =
                <&macro_press>,
                <&kp LEFT_ALT>,
                <&macro_tap>,
                <&kp KP_NUMBER_9 &kp KP_NUMBER_1 &kp KP_NUMBER_3>,
                <&macro_release>,
                <&kp LEFT_ALT>;

            label = "ALPHA_UPPER";
            wait-ms = <1>;
            tap-ms = <1>;
        };

        beta_lower: beta_lower {
            compatible = "zmk,behavior-macro";
            #binding-cells = <0>;
            bindings =
                <&macro_press>,
                <&kp LEFT_ALT>,
                <&macro_tap>,
                <&kp KP_NUMBER_2 &kp KP_NUMBER_2 &kp KP_NUMBER_5>,
                <&macro_release>,
                <&kp LEFT_ALT>;

            label = "BETA_LOWER";
            wait-ms = <1>;
            tap-ms = <1>;
        };

        beta_upper: beta_upper {
            compatible = "zmk,behavior-macro";
            #binding-cells = <0>;
            bindings =
                <&macro_press>,
                <&kp LEFT_ALT>,
                <&macro_tap>,
                <&kp KP_NUMBER_9 &kp KP_NUMBER_1 &kp KP_NUMBER_4>,
                <&macro_release>,
                <&kp LEFT_ALT>;

            label = "BETA_UPPER";
            wait-ms = <1>;
            tap-ms = <1>;
        };

        gamma_lower: gamma_lower {
            compatible = "zmk,behavior-macro";
            #binding-cells = <0>;
            bindings =
                <&macro_press>,
                <&kp LEFT_ALT>,
                <&macro_tap>,
                <&kp KP_NUMBER_9 &kp KP_NUMBER_4 &kp KP_NUMBER_7>,
                <&macro_release>,
                <&kp LEFT_ALT>;

            label = "GAMMA_LOWER";
            wait-ms = <1>;
            tap-ms = <1>;
        };

        gamma_upper: gamma_upper {
            compatible = "zmk,behavior-macro";
            #binding-cells = <0>;
            bindings =
                <&macro_press>,
                <&kp LEFT_ALT>,
                <&macro_tap>,
                <&kp KP_NUMBER_9 &kp KP_NUMBER_1 &kp KP_NUMBER_5>,
                <&macro_release>,
                <&kp LEFT_ALT>;

            label = "GAMMA_UPPER";
            wait-ms = <1>;
            tap-ms = <1>;
        };

        delta_lower: delta_lower {
            compatible = "zmk,behavior-macro";
            #binding-cells = <0>;
            bindings =
                <&macro_press>,
                <&kp LEFT_ALT>,
                <&macro_tap>,
                <&kp KP_NUMBER_2 &kp KP_NUMBER_3 &kp KP_NUMBER_5>,
                <&macro_release>,
                <&kp LEFT_ALT>;

            label = "DELTA_LOWER";
            wait-ms = <1>;
            tap-ms = <1>;
        };

        delta_upper: delta_upper {
            compatible = "zmk,behavior-macro";
            #binding-cells = <0>;
            bindings =
                <&macro_press>,
                <&kp LEFT_ALT>,
                <&macro_tap>,
                <&kp KP_NUMBER_9 &kp KP_NUMBER_1 &kp KP_NUMBER_6>,
                <&macro_release>,
                <&kp LEFT_ALT>;

            label = "DELTA_UPPER";
            wait-ms = <1>;
            tap-ms = <1>;
        };

        epsilon_lower: epsilon_lower {
            compatible = "zmk,behavior-macro";
            #binding-cells = <0>;
            bindings =
                <&macro_press>,
                <&kp LEFT_ALT>,
                <&macro_tap>,
                <&kp KP_NUMBER_2 &kp KP_NUMBER_3 &kp KP_NUMBER_8>,
                <&macro_release>,
                <&kp LEFT_ALT>;

            label = "EPSILON_LOWER";
            wait-ms = <1>;
            tap-ms = <1>;
        };

        epsilon_upper: epsilon_upper {
            compatible = "zmk,behavior-macro";
            #binding-cells = <0>;
            bindings =
                <&macro_press>,
                <&kp LEFT_ALT>,
                <&macro_tap>,
                <&kp KP_NUMBER_9 &kp KP_NUMBER_1 &kp KP_NUMBER_7>,
                <&macro_release>,
                <&kp LEFT_ALT>;

            label = "EPSILON_UPPER";
            wait-ms = <1>;
            tap-ms = <1>;
        };

        zeta_lower: zeta_lower {
            compatible = "zmk,behavior-macro";
            #binding-cells = <0>;
            bindings =
                <&macro_press>,
                <&kp LEFT_ALT>,
                <&macro_tap>,
                <&kp KP_NUMBER_9 &kp KP_NUMBER_5 &kp KP_NUMBER_0>,
                <&macro_release>,
                <&kp LEFT_ALT>;

            label = "ZETA_LOWER";
            wait-ms = <1>;
            tap-ms = <1>;
        };

        zeta_upper: zeta_upper {
            compatible = "zmk,behavior-macro";
            #binding-cells = <0>;
            bindings =
                <&macro_press>,
                <&kp LEFT_ALT>,
                <&macro_tap>,
                <&kp KP_NUMBER_9 &kp KP_NUMBER_1 &kp LC(KP_NUMBER_8)>,
                <&macro_release>,
                <&kp LEFT_ALT>;

            label = "ZETA_UPPER";
            wait-ms = <1>;
            tap-ms = <1>;
        };

        eta_lower: eta_lower {
            compatible = "zmk,behavior-macro";
            #binding-cells = <0>;
            bindings =
                <&macro_press>,
                <&kp LEFT_ALT>,
                <&macro_tap>,
                <&kp KP_NUMBER_9 &kp KP_NUMBER_5 &kp KP_NUMBER_1>,
                <&macro_release>,
                <&kp LEFT_ALT>;

            label = "ETA_LOWER";
            wait-ms = <1>;
            tap-ms = <1>;
        };

        eta_upper: eta_upper {
            compatible = "zmk,behavior-macro";
            #binding-cells = <0>;
            bindings =
                <&macro_press>,
                <&kp LEFT_ALT>,
                <&macro_tap>,
                <&kp KP_NUMBER_9 &kp KP_NUMBER_1 &kp LC(KP_NUMBER_9)>,
                <&macro_release>,
                <&kp LEFT_ALT>;

            label = "ETA_UPPER";
            wait-ms = <1>;
            tap-ms = <1>;
        };

        theta_lower: theta_lower {
            compatible = "zmk,behavior-macro";
            #binding-cells = <0>;
            bindings =
                <&macro_press>,
                <&kp LEFT_ALT>,
                <&macro_tap>,
                <&kp KP_NUMBER_9 &kp KP_NUMBER_5 &kp KP_NUMBER_2>,
                <&macro_release>,
                <&kp LEFT_ALT>;

            label = "THETA_LOWER";
            wait-ms = <1>;
            tap-ms = <1>;
        };

        theta_upper: theta_upper {
            compatible = "zmk,behavior-macro";
            #binding-cells = <0>;
            bindings =
                <&macro_press>,
                <&kp LEFT_ALT>,
                <&macro_tap>,
                <&kp KP_NUMBER_9 &kp KP_NUMBER_2 &kp KP_NUMBER_0>,
                <&macro_release>,
                <&kp LEFT_ALT>;

            label = "THETA_UPPER";
            wait-ms = <1>;
            tap-ms = <1>;
        };

        iota_lower: iota_lower {
            compatible = "zmk,behavior-macro";
            #binding-cells = <0>;
            bindings =
                <&macro_press>,
                <&kp LEFT_ALT>,
                <&macro_tap>,
                <&kp KP_NUMBER_9 &kp KP_NUMBER_5 &kp KP_NUMBER_3>,
                <&macro_release>,
                <&kp LEFT_ALT>;

            label = "IOTA_LOWER";
            wait-ms = <1>;
            tap-ms = <1>;
        };

        iota_upper: iota_upper {
            compatible = "zmk,behavior-macro";
            #binding-cells = <0>;
            bindings =
                <&macro_press>,
                <&kp LEFT_ALT>,
                <&macro_tap>,
                <&kp KP_NUMBER_9 &kp KP_NUMBER_2 &kp KP_NUMBER_1>,
                <&macro_release>,
                <&kp LEFT_ALT>;

            label = "IOTA_UPPER";
            wait-ms = <1>;
            tap-ms = <1>;
        };

        kappa_lower: kappa_lower {
            compatible = "zmk,behavior-macro";
            #binding-cells = <0>;
            bindings =
                <&macro_press>,
                <&kp LEFT_ALT>,
                <&macro_tap>,
                <&kp KP_NUMBER_9 &kp KP_NUMBER_5 &kp KP_NUMBER_4>,
                <&macro_release>,
                <&kp LEFT_ALT>;

            label = "KAPPA_LOWER";
            wait-ms = <1>;
            tap-ms = <1>;
        };

        kappa_upper: kappa_upper {
            compatible = "zmk,behavior-macro";
            #binding-cells = <0>;
            bindings =
                <&macro_press>,
                <&kp LEFT_ALT>,
                <&macro_tap>,
                <&kp KP_NUMBER_9 &kp KP_NUMBER_2 &kp KP_NUMBER_2>,
                <&macro_release>,
                <&kp LEFT_ALT>;

            label = "KAPPA_UPPER";
            wait-ms = <1>;
            tap-ms = <1>;
        };

        lambda_lower: lambda_lower {
            compatible = "zmk,behavior-macro";
            #binding-cells = <0>;
            bindings =
                <&macro_press>,
                <&kp LEFT_ALT>,
                <&macro_tap>,
                <&kp KP_NUMBER_9 &kp KP_NUMBER_5 &kp KP_NUMBER_5>,
                <&macro_release>,
                <&kp LEFT_ALT>;

            label = "LAMBDA_LOWER";
            wait-ms = <1>;
            tap-ms = <1>;
        };

        lambda_upper: lambda_upper {
            compatible = "zmk,behavior-macro";
            #binding-cells = <0>;
            bindings =
                <&macro_press>,
                <&kp LEFT_ALT>,
                <&macro_tap>,
                <&kp KP_NUMBER_9 &kp KP_NUMBER_2 &kp KP_NUMBER_3>,
                <&macro_release>,
                <&kp LEFT_ALT>;

            label = "LAMBDA_UPPER";
            wait-ms = <1>;
            tap-ms = <1>;
        };

        mu_lower: mu_lower {
            compatible = "zmk,behavior-macro";
            #binding-cells = <0>;
            bindings =
                <&macro_press>,
                <&kp LEFT_ALT>,
                <&macro_tap>,
                <&kp KP_NUMBER_9 &kp KP_NUMBER_5 &kp KP_NUMBER_6>,
                <&macro_release>,
                <&kp LEFT_ALT>;

            label = "MU_LOWER";
            wait-ms = <1>;
            tap-ms = <1>;
        };

        mu_upper: mu_upper {
            compatible = "zmk,behavior-macro";
            #binding-cells = <0>;
            bindings =
                <&macro_press>,
                <&kp LEFT_ALT>,
                <&macro_tap>,
                <&kp KP_NUMBER_9 &kp KP_NUMBER_2 &kp KP_NUMBER_4>,
                <&macro_release>,
                <&kp LEFT_ALT>;

            label = "MU_UPPER";
            wait-ms = <1>;
            tap-ms = <1>;
        };

        nu_lower: nu_lower {
            compatible = "zmk,behavior-macro";
            #binding-cells = <0>;
            bindings =
                <&macro_press>,
                <&kp LEFT_ALT>,
                <&macro_tap>,
                <&kp KP_NUMBER_9 &kp KP_NUMBER_5 &kp KP_NUMBER_7>,
                <&macro_release>,
                <&kp LEFT_ALT>;

            label = "NU_LOWER";
            wait-ms = <1>;
            tap-ms = <1>;
        };

        nu_upper: nu_upper {
            compatible = "zmk,behavior-macro";
            #binding-cells = <0>;
            bindings =
                <&macro_press>,
                <&kp LEFT_ALT>,
                <&macro_tap>,
                <&kp KP_NUMBER_9 &kp KP_NUMBER_2 &kp KP_NUMBER_5>,
                <&macro_release>,
                <&kp LEFT_ALT>;

            label = "NU_UPPER";
            wait-ms = <1>;
            tap-ms = <1>;
        };

        xi_lower: xi_lower {
            compatible = "zmk,behavior-macro";
            #binding-cells = <0>;
            bindings =
                <&macro_press>,
                <&kp LEFT_ALT>,
                <&macro_tap>,
                <&kp KP_NUMBER_9 &kp KP_NUMBER_5 &kp KP_NUMBER_8>,
                <&macro_release>,
                <&kp LEFT_ALT>;

            label = "XI_LOWER";
            wait-ms = <1>;
            tap-ms = <1>;
        };

        xi_upper: xi_upper {
            compatible = "zmk,behavior-macro";
            #binding-cells = <0>;
            bindings =
                <&macro_press>,
                <&kp LEFT_ALT>,
                <&macro_tap>,
                <&kp KP_NUMBER_9 &kp KP_NUMBER_2 &kp KP_NUMBER_6>,
                <&macro_release>,
                <&kp LEFT_ALT>;

            label = "XI_UPPER";
            wait-ms = <1>;
            tap-ms = <1>;
        };

        omicron_lower: omicron_lower {
            compatible = "zmk,behavior-macro";
            #binding-cells = <0>;
            bindings =
                <&macro_press>,
                <&kp LEFT_ALT>,
                <&macro_tap>,
                <&kp KP_NUMBER_9 &kp KP_NUMBER_5 &kp KP_NUMBER_9>,
                <&macro_release>,
                <&kp LEFT_ALT>;

            label = "OMICRON_LOWER";
            wait-ms = <1>;
            tap-ms = <1>;
        };

        omicron_upper: omicron_upper {
            compatible = "zmk,behavior-macro";
            #binding-cells = <0>;
            bindings =
                <&macro_press>,
                <&kp LEFT_ALT>,
                <&macro_tap>,
                <&kp KP_NUMBER_9 &kp KP_NUMBER_2 &kp KP_NUMBER_7>,
                <&macro_release>,
                <&kp LEFT_ALT>;

            label = "OMICRON_UPPER";
            wait-ms = <1>;
            tap-ms = <1>;
        };

        pi_lower: pi_lower {
            compatible = "zmk,behavior-macro";
            #binding-cells = <0>;
            bindings =
                <&macro_press>,
                <&kp LEFT_ALT>,
                <&macro_tap>,
                <&kp KP_NUMBER_9 &kp KP_NUMBER_6 &kp KP_NUMBER_0>,
                <&macro_release>,
                <&kp LEFT_ALT>;

            label = "PI_LOWER";
            wait-ms = <1>;
            tap-ms = <1>;
        };

        pi_upper: pi_upper {
            compatible = "zmk,behavior-macro";
            #binding-cells = <0>;
            bindings =
                <&macro_press>,
                <&kp LEFT_ALT>,
                <&macro_tap>,
                <&kp KP_NUMBER_9 &kp KP_NUMBER_2 &kp KP_NUMBER_8>,
                <&macro_release>,
                <&kp LEFT_ALT>;

            label = "PI_UPPER";
            wait-ms = <1>;
            tap-ms = <1>;
        };

        rho_lower: rho_lower {
            compatible = "zmk,behavior-macro";
            #binding-cells = <0>;
            bindings =
                <&macro_press>,
                <&kp LEFT_ALT>,
                <&macro_tap>,
                <&kp KP_NUMBER_9 &kp KP_NUMBER_6 &kp KP_NUMBER_1>,
                <&macro_release>,
                <&kp LEFT_ALT>;

            label = "RHO_LOWER";
            wait-ms = <1>;
            tap-ms = <1>;
        };

        rho_upper: rho_upper {
            compatible = "zmk,behavior-macro";
            #binding-cells = <0>;
            bindings =
                <&macro_press>,
                <&kp LEFT_ALT>,
                <&macro_tap>,
                <&kp KP_NUMBER_9 &kp KP_NUMBER_2 &kp KP_NUMBER_9>,
                <&macro_release>,
                <&kp LEFT_ALT>;

            label = "RHO_UPPER";
            wait-ms = <1>;
            tap-ms = <1>;
        };

        sigma_lower: sigma_lower {
            compatible = "zmk,behavior-macro";
            #binding-cells = <0>;
            bindings =
                <&macro_press>,
                <&kp LEFT_ALT>,
                <&macro_tap>,
                <&kp KP_NUMBER_9 &kp KP_NUMBER_6 &kp KP_NUMBER_3>,
                <&macro_release>,
                <&kp LEFT_ALT>;

            label = "SIGMA_LOWER";
            wait-ms = <1>;
            tap-ms = <1>;
        };

        sigma_upper: sigma_upper {
            compatible = "zmk,behavior-macro";
            #binding-cells = <0>;
            bindings =
                <&macro_press>,
                <&kp LEFT_ALT>,
                <&macro_tap>,
                <&kp KP_NUMBER_9 &kp KP_NUMBER_3 &kp KP_NUMBER_1>,
                <&macro_release>,
                <&kp LEFT_ALT>;

            label = "SIGMA_UPPER";
            wait-ms = <1>;
            tap-ms = <1>;
        };

        tau_lower: tau_lower {
            compatible = "zmk,behavior-macro";
            #binding-cells = <0>;
            bindings =
                <&macro_press>,
                <&kp LEFT_ALT>,
                <&macro_tap>,
                <&kp KP_NUMBER_9 &kp KP_NUMBER_6 &kp KP_NUMBER_4>,
                <&macro_release>,
                <&kp LEFT_ALT>;

            label = "TAU_LOWER";
            wait-ms = <1>;
            tap-ms = <1>;
        };

        tau_upper: tau_upper {
            compatible = "zmk,behavior-macro";
            #binding-cells = <0>;
            bindings =
                <&macro_press>,
                <&kp LEFT_ALT>,
                <&macro_tap>,
                <&kp KP_NUMBER_9 &kp KP_NUMBER_3 &kp KP_NUMBER_2>,
                <&macro_release>,
                <&kp LEFT_ALT>;

            label = "TAU_UPPER";
            wait-ms = <1>;
            tap-ms = <1>;
        };

        upsilon_lower: upsilon_lower {
            compatible = "zmk,behavior-macro";
            #binding-cells = <0>;
            bindings =
                <&macro_press>,
                <&kp LEFT_ALT>,
                <&macro_tap>,
                <&kp KP_NUMBER_9 &kp KP_NUMBER_6 &kp KP_NUMBER_5>,
                <&macro_release>,
                <&kp LEFT_ALT>;

            label = "UPSILON_LOWER";
            wait-ms = <1>;
            tap-ms = <1>;
        };

        upsilon_upper: upsilon_upper {
            compatible = "zmk,behavior-macro";
            #binding-cells = <0>;
            bindings =
                <&macro_press>,
                <&kp LEFT_ALT>,
                <&macro_tap>,
                <&kp KP_NUMBER_9 &kp KP_NUMBER_7 &kp KP_NUMBER_8>,
                <&macro_release>,
                <&kp LEFT_ALT>;

            label = "UPSILON_UPPER";
            wait-ms = <1>;
            tap-ms = <1>;
        };

        phi_lower: phi_lower {
            compatible = "zmk,behavior-macro";
            #binding-cells = <0>;
            bindings =
                <&macro_press>,
                <&kp LEFT_ALT>,
                <&macro_tap>,
                <&kp KP_NUMBER_9 &kp KP_NUMBER_6 &kp KP_NUMBER_6>,
                <&macro_release>,
                <&kp LEFT_ALT>;

            label = "PHI_LOWER";
            wait-ms = <1>;
            tap-ms = <1>;
        };

        phi_upper: phi_upper {
            compatible = "zmk,behavior-macro";
            #binding-cells = <0>;
            bindings =
                <&macro_press>,
                <&kp LEFT_ALT>,
                <&macro_tap>,
                <&kp KP_NUMBER_9 &kp KP_NUMBER_3 &kp KP_NUMBER_4>,
                <&macro_release>,
                <&kp LEFT_ALT>;

            label = "PHI_UPPER";
            wait-ms = <1>;
            tap-ms = <1>;
        };

        chi_lower: chi_lower {
            compatible = "zmk,behavior-macro";
            #binding-cells = <0>;
            bindings =
                <&macro_press>,
                <&kp LEFT_ALT>,
                <&macro_tap>,
                <&kp KP_NUMBER_9 &kp KP_NUMBER_6 &kp KP_NUMBER_7>,
                <&macro_release>,
                <&kp LEFT_ALT>;

            label = "CHI_LOWER";
            wait-ms = <1>;
            tap-ms = <1>;
        };

        chi_upper: chi_upper {
            compatible = "zmk,behavior-macro";
            #binding-cells = <0>;
            bindings =
                <&macro_press>,
                <&kp LEFT_ALT>,
                <&macro_tap>,
                <&kp KP_NUMBER_9 &kp KP_NUMBER_3 &kp KP_NUMBER_5>,
                <&macro_release>,
                <&kp LEFT_ALT>;

            label = "CHI_UPPER";
            wait-ms = <1>;
            tap-ms = <1>;
        };

        psi_lower: psi_lower {
            compatible = "zmk,behavior-macro";
            #binding-cells = <0>;
            bindings =
                <&macro_press>,
                <&kp LEFT_ALT>,
                <&macro_tap>,
                <&kp KP_NUMBER_9 &kp KP_NUMBER_6 &kp KP_NUMBER_8>,
                <&macro_release>,
                <&kp LEFT_ALT>;

            label = "PSI_LOWER";
            wait-ms = <1>;
            tap-ms = <1>;
        };

        psi_upper: psi_upper {
            compatible = "zmk,behavior-macro";
            #binding-cells = <0>;
            bindings =
                <&macro_press>,
                <&kp LEFT_ALT>,
                <&macro_tap>,
                <&kp KP_NUMBER_9 &kp KP_NUMBER_3 &kp KP_NUMBER_6>,
                <&macro_release>,
                <&kp LEFT_ALT>;

            label = "PSI_UPPER";
            wait-ms = <1>;
            tap-ms = <1>;
        };

        omega_lower: omega_lower {
            compatible = "zmk,behavior-macro";
            #binding-cells = <0>;
            bindings =
                <&macro_press>,
                <&kp LEFT_ALT>,
                <&macro_tap>,
                <&kp KP_NUMBER_9 &kp KP_NUMBER_6 &kp KP_NUMBER_9>,
                <&macro_release>,
                <&kp LEFT_ALT>;

            label = "OMEGA_LOWER";
            wait-ms = <1>;
            tap-ms = <1>;
        };

        omega_upper: omega_upper {
            compatible = "zmk,behavior-macro";
            #binding-cells = <0>;
            bindings =
                <&macro_press>,
                <&kp LEFT_ALT>,
                <&macro_tap>,
                <&kp KP_NUMBER_9 &kp KP_NUMBER_3 &kp KP_NUMBER_7>,
                <&macro_release>,
                <&kp LEFT_ALT>;

            label = "OMEGA_UPPER";
            wait-ms = <1>;
            tap-ms = <1>;
        };

        sigmaf_lower: sigmaf_lower {
            compatible = "zmk,behavior-macro";
            #binding-cells = <0>;
            bindings =
                <&macro_press>,
                <&kp LEFT_ALT>,
                <&macro_tap>,
                <&kp KP_NUMBER_9 &kp KP_NUMBER_6 &kp KP_NUMBER_2>,
                <&macro_release>,
                <&kp LEFT_ALT>;

            label = "SIGMAF_LOWER";
            wait-ms = <1>;
            tap-ms = <1>;
        };

        zero_subscript: zero_subscript {
            compatible = "zmk,behavior-macro";
            #binding-cells = <0>;
            bindings =
                <&macro_press>,
                <&kp LEFT_ALT>,
                <&macro_tap>,
                <&kp KP_NUMBER_8 &kp KP_NUMBER_3 &kp KP_NUMBER_2 &kp KP_NUMBER_0>,
                <&macro_release>,
                <&kp LEFT_ALT>;

            label = "ZERO_SUBSCRIPT";
            wait-ms = <1>;
            tap-ms = <1>;
        };

        one_subscript: one_subscript {
            compatible = "zmk,behavior-macro";
            #binding-cells = <0>;
            bindings =
                <&macro_press>,
                <&kp LEFT_ALT>,
                <&macro_tap>,
                <&kp KP_NUMBER_8 &kp KP_NUMBER_3 &kp KP_NUMBER_2 &kp KP_NUMBER_1>,
                <&macro_release>,
                <&kp LEFT_ALT>;

            label = "ONE_SUBSCRIPT";
            wait-ms = <1>;
            tap-ms = <1>;
        };

        two_subscript: two_subscript {
            compatible = "zmk,behavior-macro";
            #binding-cells = <0>;
            bindings =
                <&macro_press>,
                <&kp LEFT_ALT>,
                <&macro_tap>,
                <&kp KP_NUMBER_8 &kp KP_NUMBER_3 &kp KP_NUMBER_2 &kp KP_NUMBER_2>,
                <&macro_release>,
                <&kp LEFT_ALT>;

            label = "TWO_SUBSCRIPT";
            wait-ms = <1>;
            tap-ms = <1>;
        };

        three_subscript: three_subscript {
            compatible = "zmk,behavior-macro";
            #binding-cells = <0>;
            bindings =
                <&macro_press>,
                <&kp LEFT_ALT>,
                <&macro_tap>,
                <&kp KP_NUMBER_8 &kp KP_NUMBER_3 &kp KP_NUMBER_2 &kp KP_NUMBER_3>,
                <&macro_release>,
                <&kp LEFT_ALT>;

            label = "THREE_SUBSCRIPT";
            wait-ms = <1>;
            tap-ms = <1>;
        };

        four_subscript: four_subscript {
            compatible = "zmk,behavior-macro";
            #binding-cells = <0>;
            bindings =
                <&macro_press>,
                <&kp LEFT_ALT>,
                <&macro_tap>,
                <&kp KP_NUMBER_8 &kp KP_NUMBER_3 &kp KP_NUMBER_2 &kp KP_NUMBER_4>,
                <&macro_release>,
                <&kp LEFT_ALT>;

            label = "FOUR_SUBSCRIPT";
            wait-ms = <1>;
            tap-ms = <1>;
        };

        five_subscript: five_subscript {
            compatible = "zmk,behavior-macro";
            #binding-cells = <0>;
            bindings =
                <&macro_press>,
                <&kp LEFT_ALT>,
                <&macro_tap>,
                <&kp KP_NUMBER_8 &kp KP_NUMBER_3 &kp KP_NUMBER_2 &kp KP_NUMBER_5>,
                <&macro_release>,
                <&kp LEFT_ALT>;

            label = "FIVE_SUBSCRIPT";
            wait-ms = <1>;
            tap-ms = <1>;
        };

        six_subscript: six_subscript {
            compatible = "zmk,behavior-macro";
            #binding-cells = <0>;
            bindings =
                <&macro_press>,
                <&kp LEFT_ALT>,
                <&macro_tap>,
                <&kp KP_NUMBER_8 &kp KP_NUMBER_3 &kp KP_NUMBER_2 &kp KP_NUMBER_6>,
                <&macro_release>,
                <&kp LEFT_ALT>;

            label = "SIX_SUBSCRIPT";
            wait-ms = <1>;
            tap-ms = <1>;
        };

        seven_subscript: seven_subscript {
            compatible = "zmk,behavior-macro";
            #binding-cells = <0>;
            bindings =
                <&macro_press>,
                <&kp LEFT_ALT>,
                <&macro_tap>,
                <&kp KP_NUMBER_8 &kp KP_NUMBER_3 &kp KP_NUMBER_2 &kp KP_NUMBER_7>,
                <&macro_release>,
                <&kp LEFT_ALT>;

            label = "SEVEN_SUBSCRIPT";
            wait-ms = <1>;
            tap-ms = <1>;
        };

        eight_subscript: eight_subscript {
            compatible = "zmk,behavior-macro";
            #binding-cells = <0>;
            bindings =
                <&macro_press>,
                <&kp LEFT_ALT>,
                <&macro_tap>,
                <&kp KP_NUMBER_8 &kp KP_NUMBER_3 &kp KP_NUMBER_2 &kp KP_NUMBER_8>,
                <&macro_release>,
                <&kp LEFT_ALT>;

            label = "EIGHT_SUBSCRIPT";
            wait-ms = <1>;
            tap-ms = <1>;
        };

        nine_subscript: nine_subscript {
            compatible = "zmk,behavior-macro";
            #binding-cells = <0>;
            bindings =
                <&macro_press>,
                <&kp LEFT_ALT>,
                <&macro_tap>,
                <&kp KP_NUMBER_8 &kp KP_NUMBER_3 &kp KP_NUMBER_2 &kp KP_NUMBER_9>,
                <&macro_release>,
                <&kp LEFT_ALT>;

            label = "NINE_SUBSCRIPT";
            wait-ms = <1>;
            tap-ms = <1>;
        };

        tm_superscript: tm_superscript {
            compatible = "zmk,behavior-macro";
            #binding-cells = <0>;
            bindings =
                <&macro_press>,
                <&kp LEFT_ALT>,
                <&macro_tap>,
                <&kp KP_NUMBER_0 &kp KP_NUMBER_1 &kp KP_NUMBER_5 &kp KP_NUMBER_3>,
                <&macro_release>,
                <&kp LEFT_ALT>;

            label = "TM_SUPERSCRIPT";
            wait-ms = <1>;
            tap-ms = <1>;
        };

        reg_superscript: reg_superscript {
            compatible = "zmk,behavior-macro";
            #binding-cells = <0>;
            bindings =
                <&macro_press>,
                <&kp LEFT_ALT>,
                <&macro_tap>,
                <&kp KP_NUMBER_0 &kp KP_NUMBER_1 &kp KP_NUMBER_7 &kp KP_NUMBER_4>,
                <&macro_release>,
                <&kp LEFT_ALT>;

            label = "REG_SUPERSCRIPT";
            wait-ms = <1>;
            tap-ms = <1>;
        };

        copy_superscript: copy_superscript {
            compatible = "zmk,behavior-macro";
            #binding-cells = <0>;
            bindings =
                <&macro_press>,
                <&kp LEFT_ALT>,
                <&macro_tap>,
                <&kp KP_NUMBER_0 &kp KP_NUMBER_1 &kp KP_NUMBER_6 &kp KP_NUMBER_9>,
                <&macro_release>,
                <&kp LEFT_ALT>;

            label = "COPY_SUPERSCRIPT";
            wait-ms = <1>;
            tap-ms = <1>;
        };
    };

    keymap {
        compatible = "zmk,keymap";

        default_layer {
            label = "QWRT";
            bindings = <
&kp ESCAPE        &kp N1     &kp N2    &kp N3    &kp N4  &kp N5                   &kp N6       &kp N7  &kp N8     &lmt2 MCLK N9  &lt 6 N0   &kp BSPC
&kp TAB           &kp Q      &kp W     &kp E     &kp R   &kp T                    &kp Y        &kp U   &kp I      &kp O          &kp P      &to 1
&kp CAPS          &kp A      &kp S     &kp D     &kp F   &kp G                    &kp H        &kp J   &kp K      &kp L          &kp SQT    &kp ENTER
&kp LEFT_SHIFT    &kp Z      &kp X     &kp C     &kp V   &kp B      &kp N  &kp B  &kp N        &kp M   &kp COMMA  &kp DOT        &kp FSLH   &kp RSHFT
&kp LEFT_CONTROL  &kp GRAVE  &kp LGUI  &kp LALT  &mo 9   &kp SPACE  &mo 4  &mo 4  &lt 8 SPACE                                    &kp EQUAL  &kp RCTRL
            >;
        };

        mouse_layer {
            label = "MOUSE";
            bindings = <
&trans  &trans  &trans  &trans  &trans  &trans                             &kp HOME        &kp ESCAPE       &kp TAB       &mkp RCLK  &mo 6         &kp LEFT_SHIFT
&trans  &trans  &trans  &trans  &trans  &trans                             &kp END         &kp ENTER        &mkp LCLK     &mkp MCLK  &kp LEFT_ALT  &kp LEFT_CONTROL
&trans  &trans  &trans  &trans  &trans  &trans                             &kp UP_ARROW    &kp BACKSPACE    &kp DELETE    &mo 7      &kp PG_UP     &lt 3 ENTER
&trans  &trans  &trans  &trans  &trans  &trans  &trans     &kp LEFT_ARROW  &kp DOWN_ARROW  &kp RIGHT_ARROW  &kp LEFT_WIN  &none      &kp PG_DN     &none
&trans  &trans  &trans  &trans  &trans  &trans  &lmt0 4 1  &lmt0 4 1       &lt 2 SPACE                                               &trans        &none
            >;
        };

        mouse2_layer {
            label = "MOUSE2";
            bindings = <
&trans  &trans  &trans  &trans  &trans  &trans                  &kp HOME  &kp ESCAPE     &kp TAB         &kp UP_ARROW    &kp RIGHT_ARROW  &kp LEFT_SHIFT
&trans  &trans  &trans  &trans  &trans  &trans                  &kp END   &kp ENTER      &kp LEFT_ARROW  &kp DOWN_ARROW  &kp LEFT_ALT     &kp LEFT_CONTROL
&trans  &trans  &trans  &trans  &trans  &trans                  &trans    &kp BACKSPACE  &kp DELETE      &mo 7           &kp PG_UP        &lt 3 ENTER
&trans  &trans  &trans  &trans  &trans  &trans  &trans  &trans  &trans    &trans         &kp LEFT_WIN    &trans          &kp PG_DN        &trans
&trans  &trans  &trans  &trans  &trans  &trans  &trans  &trans  &trans                                                   &trans           &none
            >;
        };

        spacemouse_layer {
            label = "SPACE";
            bindings = <
&trans  &trans  &trans  &trans  &trans  &trans                  &kp HOME  &kp ESCAPE     &kp TAB       &mo 10  &mo 12     &kp LEFT_SHIFT
&trans  &trans  &trans  &trans  &trans  &trans                  &kp END   &kp ENTER      &mo 11        &mo 10  &mo 12     &kp LEFT_CONTROL
&trans  &trans  &trans  &trans  &trans  &trans                  &trans    &kp BACKSPACE  &mo 11        &mo 7   &kp PG_UP  &none
&trans  &trans  &trans  &trans  &trans  &trans  &trans  &trans  &trans    &trans         &kp LEFT_WIN  &trans  &kp PG_DN  &trans
&trans  &trans  &trans  &trans  &trans  &trans  &trans  &trans  &trans                                         &trans     &none
            >;
        };

        number_layer {
            bindings = <
&trans  &kp F1             &kp F2         &kp F3          &kp F4                   &kp F5                                         &kp HOME        &kp N7           &kp N8  &kp N9      &plus_leftparenthesis  &kp DELETE
&trans  &bt BT_CLR         &kp PAGE_UP    &kp C_MUTE      &volume_brightness_down  &volume_brightness_up                          &kp END         &kp N4           &kp N5  &kp N6      &kp MINUS              &kp F11
&trans  &ext_power EP_TOG  &kp PAGE_DOWN  &kp C_PREVIOUS  &kp C_PLAY_PAUSE         &kp C_NEXT                                     &kp UP_ARROW    &kp N1           &kp N2  &kp N3      &kp ASTERISK           &trans
&trans  &bt BT_SEL 0       &bt BT_SEL 1   &bt BT_SEL 2    &bt BT_SEL 3             &bt BT_SEL 4           &kp F6  &kp LEFT_ARROW  &kp DOWN_ARROW  &kp RIGHT_ARROW  &kp N0  &kp PERIOD  &kp SLASH              &trans
&trans  &trans             &trans         &trans          &trans                   &trans                 &trans  &trans          &trans                                               &kp EQUAL              &trans
            >;

            label = "NUM";
        };

        function_layer {
            label = "FUN";
            bindings = <
&trans  &trans  &trans  &trans  &trans  &trans                  &trans  &trans  &trans  &trans  &trans  &trans
&trans  &trans  &trans  &trans  &trans  &trans                  &trans  &trans  &trans  &trans  &trans  &trans
&trans  &trans  &trans  &trans  &trans  &trans                  &trans  &trans  &trans  &trans  &trans  &trans
&trans  &trans  &trans  &trans  &trans  &trans  &trans  &trans  &trans  &trans  &trans  &trans  &trans  &trans
&trans  &trans  &trans  &trans  &trans  &trans  &trans  &trans  &trans                          &trans  &trans
            >;
        };

        scroll_layer {
            label = "SCROLL";
            bindings = <
&trans  &trans  &trans  &trans  &trans  &trans                  &trans  &trans  &trans  &trans  &trans  &trans
&trans  &trans  &trans  &trans  &trans  &trans                  &trans  &trans  &trans  &trans  &trans  &trans
&trans  &trans  &trans  &trans  &trans  &trans                  &trans  &trans  &trans  &trans  &trans  &trans
&trans  &trans  &trans  &trans  &trans  &trans  &trans  &trans  &trans  &trans  &trans  &trans  &trans  &trans
&trans  &trans  &trans  &trans  &trans  &trans  &trans  &trans  &trans                          &trans  &trans
            >;
        };

        snipe_layer {
            label = "SNIPE";
            bindings = <
&trans  &trans  &trans  &trans  &trans  &trans                  &trans  &trans  &trans  &trans  &trans  &trans
&trans  &trans  &trans  &trans  &trans  &trans                  &trans  &trans  &trans  &trans  &trans  &trans
&trans  &trans  &trans  &trans  &trans  &trans                  &trans  &trans  &trans  &trans  &trans  &trans
&trans  &trans  &trans  &trans  &trans  &trans  &trans  &trans  &trans  &trans  &trans  &trans  &trans  &trans
&trans  &trans  &trans  &trans  &trans  &trans  &trans  &trans  &trans                          &trans  &trans
            >;
        };

        special_layer {
            bindings = <
&trans  &pipe_exclamationmarkreverse  &trans  &trans             &trans            &trans                                   &trans    &trans    &trans                    &bracket_brace_left      &bracket_brace_right            &trans
&trans  &trans                        &trans  &e_acute           &reg_superscript  &tm_superscript                          &trans    &u_acute  &i_acute                  &o_acute                 &kp MINUS                       &trans
&trans  &a_acute                      &trans  &degree_symbol     &trans            &trans                                   &trans    &trans    &trans                    &trans                   &trans                          &trans
&trans  &trans                        &trans  &copy_superscript  &u_diaeresis      &trans           &trans  &trans          &n_tilde  &trans    &semicolon_lessthanequal  &colon_greaterthanequal  &backslash_questionmarkreverse  &trans
&trans  &plusminus_almostequal        &trans  &trans             &trans            &trans           &trans  &kp KP_NUMLOCK  &trans                                                                 &approxequal_notequal           &trans
            >;

            label = "SPECIAL";
        };

        greek_layer {
            bindings = <
&trans  &one_script  &two_script  &three_script  &four_script   &five_script                   &six_script  &seven_script  &eight_script  &nine_script  &zero_script  &trans
&trans  &q_theta     &w_omega     &e_epsilon     &r_rho         &t_tau                         &y_psi       &u_upsilon     &i_iota        &o_omikron    &p_pi         &trans
&trans  &a_alpha     &s_sigma     &d_delta       &f_phi         &g_gamma                       &h_eta       &trans         &k_kappa       &l_lambda     &trans        &trans
&trans  &z_zeta      &x_xi        &c_chi         &sigmaf_lower  &b_beta       &n_nu   &b_beta  &n_nu        &m_mu          &trans         &trans        &trans        &trans
&trans  &trans       &trans       &trans         &trans         &trans        &trans  &trans   &trans                                                   &trans        &trans
            >;

            label = "GREEK";
        };

        orbit3d_layer {
            label = "3D_ORBIT";
            bindings = <
&trans  &trans  &trans  &trans  &trans  &trans                  &trans  &trans  &trans  &trans  &trans  &trans
&trans  &trans  &trans  &trans  &trans  &trans                  &trans  &trans  &trans  &trans  &trans  &trans
&trans  &trans  &trans  &trans  &trans  &trans                  &trans  &trans  &trans  &trans  &trans  &trans
&trans  &trans  &trans  &trans  &trans  &trans  &trans  &trans  &trans  &trans  &trans  &trans  &trans  &trans
&trans  &trans  &trans  &trans  &trans  &trans  &trans  &trans  &trans                          &trans  &trans
            >;
        };

        pan3d_layer {
            label = "3D_PAN";
            bindings = <
&trans  &trans  &trans  &trans  &trans  &trans                  &trans  &trans  &trans  &trans  &trans  &trans
&trans  &trans  &trans  &trans  &trans  &trans                  &trans  &trans  &trans  &trans  &trans  &trans
&trans  &trans  &trans  &trans  &trans  &trans                  &trans  &trans  &trans  &trans  &trans  &trans
&trans  &trans  &trans  &trans  &trans  &trans  &trans  &trans  &trans  &trans  &trans  &trans  &trans  &trans
&trans  &trans  &trans  &trans  &trans  &trans  &trans  &trans  &trans                          &trans  &trans
            >;
        };

        zoom3d_layer {
            label = "3D_ZOOM";
            bindings = <
&trans  &trans  &trans  &trans  &trans  &trans                  &trans  &trans  &trans  &trans  &trans  &trans
&trans  &trans  &trans  &trans  &trans  &trans                  &trans  &trans  &trans  &trans  &trans  &trans
&trans  &trans  &trans  &trans  &trans  &trans                  &trans  &trans  &trans  &trans  &trans  &trans
&trans  &trans  &trans  &trans  &trans  &trans  &trans  &trans  &trans  &trans  &trans  &trans  &trans  &trans
&trans  &trans  &trans  &trans  &trans  &trans  &trans  &trans  &trans                          &trans  &trans
            >;
        };
    };
};
